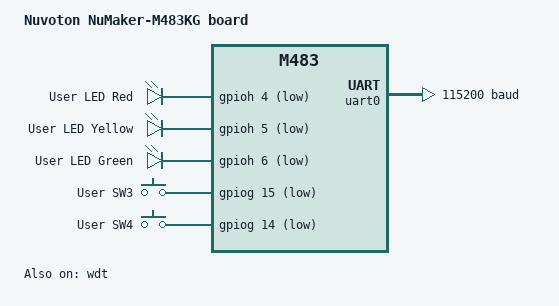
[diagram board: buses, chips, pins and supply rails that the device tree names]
/*
 * Copyright The Zephyr Project Contributors
 *
 * SPDX-License-Identifier: Apache-2.0
 */

/dts-v1/;
#include <nuvoton/m48x.dtsi>
#include "numaker_m483kg-pinctrl.dtsi"
#include <zephyr/dt-bindings/input/input-event-codes.h>

/ {
	model = "Nuvoton NuMaker-M483KG board";
	compatible = "nuvoton,numaker-m483kg", "nuvoton,m483";

	cpus {
		timebase-frequency = <DT_FREQ_M(192)>;
	};

	aliases {
		led0 = &red_led;
		led1 = &yellow_led;
		led2 = &green_led;
		sw0 = &sw3;
		sw1 = &sw4;
		watchdog0 = &wdt;
	};

	chosen {
		zephyr,console = &uart0;
		zephyr,shell-uart = &uart0;
		zephyr,sram = &sram0;
		zephyr,flash = &flash0;
	};

	leds {
		compatible = "gpio-leds";

		red_led: led_0 {
			gpios = <&gpioh 4 GPIO_ACTIVE_LOW>;
			label = "User LED Red";
		};

		yellow_led: led_1 {
			gpios = <&gpioh 5 GPIO_ACTIVE_LOW>;
			label = "User LED Yellow";
		};

		green_led: led_2 {
			gpios = <&gpioh 6 GPIO_ACTIVE_LOW>;
			label = "User LED Green";
		};
	};

	gpio_keys {
		compatible = "gpio-keys";

		sw3: button_0 {
			gpios = <&gpiog 15 GPIO_ACTIVE_LOW>;
			label = "User SW3";
			zephyr,code = <INPUT_KEY_0>;
		};

		sw4: button_1 {
			gpios = <&gpiog 14 GPIO_ACTIVE_LOW>;
			label = "User SW4";
			zephyr,code = <INPUT_KEY_1>;
		};
	};
};

&clk_lirc {
	status = "okay";
};

&clk_hxt {
	clock-frequency = <DT_FREQ_M(12)>;
	status = "okay";
};

&pll {
	clocks = <&clk_hxt>;
	status = "okay";
};

/* M483KG: 256 KB APROM flash, 128 KB SRAM */
&flash0 {
	reg = <0x0 DT_SIZE_K(256)>;
	ranges = <0x0 0x0 DT_SIZE_K(256)>;
	#address-cells = <1>;
	#size-cells = <1>;
};

&sram0 {
	reg = <0x20000000 DT_SIZE_K(128)>;
};

&gpiog {
	status = "okay";
};

&gpioh {
	status = "okay";
};

&uart0 {
	current-speed = <115200>;
	status = "okay";
	pinctrl-0 = <&uart0_default>;
	pinctrl-names = "default";
};

&wdt {
	status = "okay";
};
